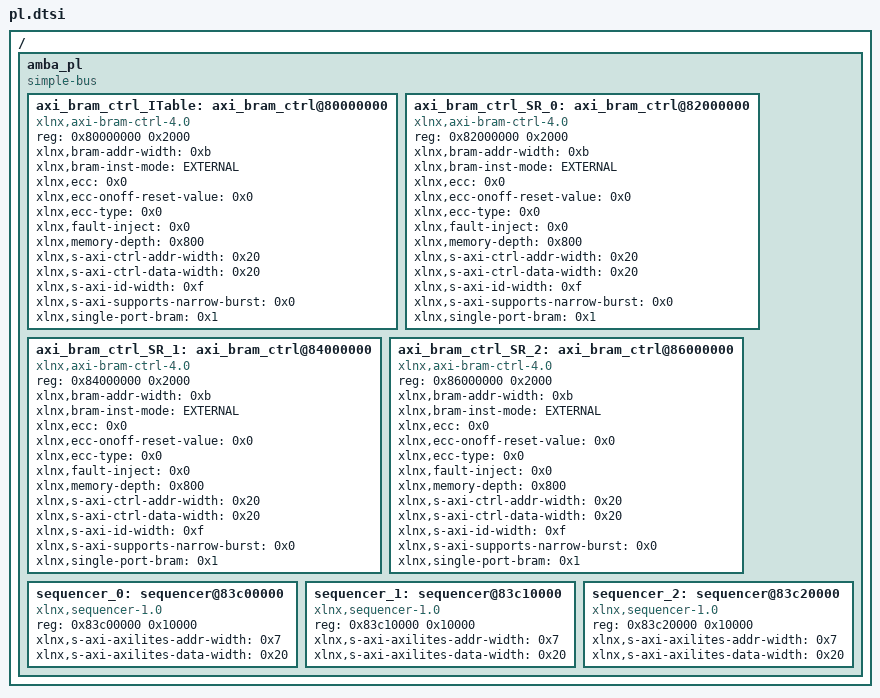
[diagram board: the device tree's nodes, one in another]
/*
 * CAUTION: This file is automatically generated by Xilinx.
 * Version: HSI 2015.4
 * Today is: Sun Apr 24 13:02:02 2016
*/


/ {
	amba_pl: amba_pl {
		#address-cells = <1>;
		#size-cells = <1>;
		compatible = "simple-bus";
		ranges ;
		axi_bram_ctrl_ITable: axi_bram_ctrl@80000000 {
			compatible = "xlnx,axi-bram-ctrl-4.0";
			reg = <0x80000000 0x2000>;
			xlnx,bram-addr-width = <0xb>;
			xlnx,bram-inst-mode = "EXTERNAL";
			xlnx,ecc = <0x0>;
			xlnx,ecc-onoff-reset-value = <0x0>;
			xlnx,ecc-type = <0x0>;
			xlnx,fault-inject = <0x0>;
			xlnx,memory-depth = <0x800>;
			xlnx,s-axi-ctrl-addr-width = <0x20>;
			xlnx,s-axi-ctrl-data-width = <0x20>;
			xlnx,s-axi-id-width = <0xf>;
			xlnx,s-axi-supports-narrow-burst = <0x0>;
			xlnx,single-port-bram = <0x1>;
		};
		axi_bram_ctrl_SR_0: axi_bram_ctrl@82000000 {
			compatible = "xlnx,axi-bram-ctrl-4.0";
			reg = <0x82000000 0x2000>;
			xlnx,bram-addr-width = <0xb>;
			xlnx,bram-inst-mode = "EXTERNAL";
			xlnx,ecc = <0x0>;
			xlnx,ecc-onoff-reset-value = <0x0>;
			xlnx,ecc-type = <0x0>;
			xlnx,fault-inject = <0x0>;
			xlnx,memory-depth = <0x800>;
			xlnx,s-axi-ctrl-addr-width = <0x20>;
			xlnx,s-axi-ctrl-data-width = <0x20>;
			xlnx,s-axi-id-width = <0xf>;
			xlnx,s-axi-supports-narrow-burst = <0x0>;
			xlnx,single-port-bram = <0x1>;
		};
		axi_bram_ctrl_SR_1: axi_bram_ctrl@84000000 {
			compatible = "xlnx,axi-bram-ctrl-4.0";
			reg = <0x84000000 0x2000>;
			xlnx,bram-addr-width = <0xb>;
			xlnx,bram-inst-mode = "EXTERNAL";
			xlnx,ecc = <0x0>;
			xlnx,ecc-onoff-reset-value = <0x0>;
			xlnx,ecc-type = <0x0>;
			xlnx,fault-inject = <0x0>;
			xlnx,memory-depth = <0x800>;
			xlnx,s-axi-ctrl-addr-width = <0x20>;
			xlnx,s-axi-ctrl-data-width = <0x20>;
			xlnx,s-axi-id-width = <0xf>;
			xlnx,s-axi-supports-narrow-burst = <0x0>;
			xlnx,single-port-bram = <0x1>;
		};
		axi_bram_ctrl_SR_2: axi_bram_ctrl@86000000 {
			compatible = "xlnx,axi-bram-ctrl-4.0";
			reg = <0x86000000 0x2000>;
			xlnx,bram-addr-width = <0xb>;
			xlnx,bram-inst-mode = "EXTERNAL";
			xlnx,ecc = <0x0>;
			xlnx,ecc-onoff-reset-value = <0x0>;
			xlnx,ecc-type = <0x0>;
			xlnx,fault-inject = <0x0>;
			xlnx,memory-depth = <0x800>;
			xlnx,s-axi-ctrl-addr-width = <0x20>;
			xlnx,s-axi-ctrl-data-width = <0x20>;
			xlnx,s-axi-id-width = <0xf>;
			xlnx,s-axi-supports-narrow-burst = <0x0>;
			xlnx,single-port-bram = <0x1>;
		};
		sequencer_0: sequencer@83c00000 {
			compatible = "xlnx,sequencer-1.0";
			reg = <0x83c00000 0x10000>;
			xlnx,s-axi-axilites-addr-width = <0x7>;
			xlnx,s-axi-axilites-data-width = <0x20>;
		};
		sequencer_1: sequencer@83c10000 {
			compatible = "xlnx,sequencer-1.0";
			reg = <0x83c10000 0x10000>;
			xlnx,s-axi-axilites-addr-width = <0x7>;
			xlnx,s-axi-axilites-data-width = <0x20>;
		};
		sequencer_2: sequencer@83c20000 {
			compatible = "xlnx,sequencer-1.0";
			reg = <0x83c20000 0x10000>;
			xlnx,s-axi-axilites-addr-width = <0x7>;
			xlnx,s-axi-axilites-data-width = <0x20>;
		};
	};
};
